# LRFDMDM32 register map
Vendor: Texas Instruments
Peripheral module from a debugger description file (folder CC27xxx15).
Registers are 32-bit, access per field, reset 0x0 unless marked. A register's access mark holds for its fields unless they carry their own. Offsets are as the file gives them; lines under a group give offsets from that group; [hi:lo] are bit positions; {n}, {i} and the like mark numbered series; 'fields as' and 'values as' point back to an identical list; <NAME> marks a mode.

## LRFDMDM32 (part 1 of 2)
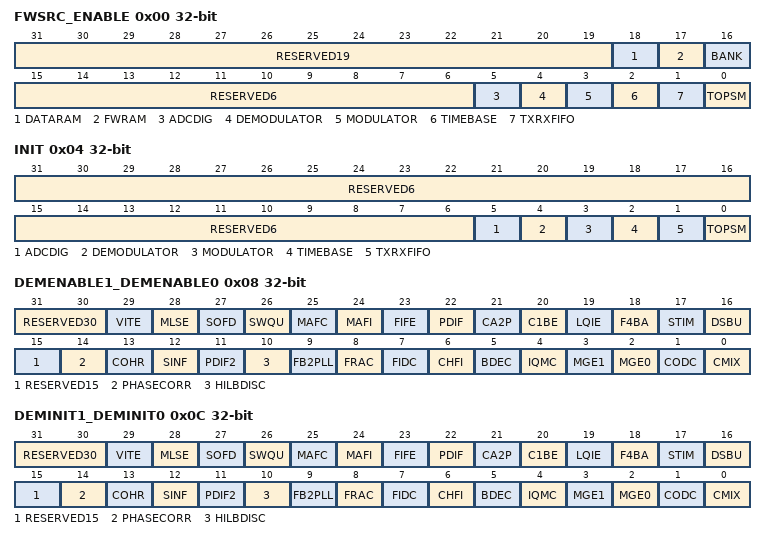
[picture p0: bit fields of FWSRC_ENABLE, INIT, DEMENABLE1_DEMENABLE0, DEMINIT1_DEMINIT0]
0x00 FWSRC_ENABLE — Internal. Only to be used through TI provided API.
  [31:19] RESERVED19 ro — Internal. Only to be used through TI provided API.
  [18] DATARAM rw — Internal. Only to be used through TI provided API.
    1=S2RRAM (Internal. Only to be used through TI provided API.); 0=MDMRAM (Internal. Only to be used through TI provided API.)
  [17] FWRAM rw — Internal. Only to be used through TI provided API.
    values as DATARAM
  [16] BANK rw — Internal. Only to be used through TI provided API.
    1=ONE (Internal. Only to be used through TI provided API.); 0=ZERO (Internal. Only to be used through TI provided API.)
  [15:6] RESERVED6 ro — Internal. Only to be used through TI provided API.
  [5] ADCDIG rw — Internal. Only to be used through TI provided API.
    1=EN (Internal. Only to be used through TI provided API.); 0=DIS (Internal. Only to be used through TI provided API.)
  [4] DEMODULATOR rw — Internal. Only to be used through TI provided API.
    values as ADCDIG
  [3] MODULATOR rw — Internal. Only to be used through TI provided API.
    values as ADCDIG
  [2] TIMEBASE rw — Internal. Only to be used through TI provided API.
    values as ADCDIG
  [1] TXRXFIFO rw — Internal. Only to be used through TI provided API.
    values as ADCDIG
  [0] TOPSM rw — Internal. Only to be used through TI provided API.
    values as ADCDIG
0x04 INIT — Internal. Only to be used through TI provided API.
  [31:6] RESERVED6 ro — Internal. Only to be used through TI provided API.
  [5] ADCDIG wo — Internal. Only to be used through TI provided API.
    1=RESET (Internal. Only to be used through TI provided API.); 0=NO_EFFECT (Internal. Only to be used through TI provided API.)
  [4] DEMODULATOR wo — Internal. Only to be used through TI provided API.
    values as ADCDIG
  [3] MODULATOR wo — Internal. Only to be used through TI provided API.
    values as ADCDIG
  [2] TIMEBASE wo — Internal. Only to be used through TI provided API.
    values as ADCDIG
  [1] TXRXFIFO wo — Internal. Only to be used through TI provided API.
    values as ADCDIG
  [0] TOPSM wo — Internal. Only to be used through TI provided API.
    values as ADCDIG
0x08 DEMENABLE1_DEMENABLE0 — Internal. Only to be used through TI provided API.
  [31:30] RESERVED30 ro — Internal. Only to be used through TI provided API.
  [29] VITE rw — Internal. Only to be used through TI provided API.
    values as FWSRC_ENABLE.ADCDIG
  [28] MLSE rw — Internal. Only to be used through TI provided API.
    values as FWSRC_ENABLE.ADCDIG
  [27] SOFD rw — Internal. Only to be used through TI provided API.
    values as FWSRC_ENABLE.ADCDIG
  [26] SWQU rw — Internal. Only to be used through TI provided API.
    values as FWSRC_ENABLE.ADCDIG
  [25] MAFC rw — Internal. Only to be used through TI provided API.
    values as FWSRC_ENABLE.ADCDIG
  [24] MAFI rw — Internal. Only to be used through TI provided API.
    values as FWSRC_ENABLE.ADCDIG
  [23] FIFE rw — Internal. Only to be used through TI provided API.
    values as FWSRC_ENABLE.ADCDIG
  [22] PDIF rw — Internal. Only to be used through TI provided API.
    values as FWSRC_ENABLE.ADCDIG
  [21] CA2P rw — Internal. Only to be used through TI provided API.
    values as FWSRC_ENABLE.ADCDIG
  [20] C1BE rw — Internal. Only to be used through TI provided API.
    values as FWSRC_ENABLE.ADCDIG
  [19] LQIE rw — Internal. Only to be used through TI provided API.
    values as FWSRC_ENABLE.ADCDIG
  [18] F4BA rw — Internal. Only to be used through TI provided API.
    values as FWSRC_ENABLE.ADCDIG
  [17] STIM rw — Internal. Only to be used through TI provided API.
    values as FWSRC_ENABLE.ADCDIG
  [16] DSBU rw — Internal. Only to be used through TI provided API.
    values as FWSRC_ENABLE.ADCDIG
  [15] RESERVED15 ro — Internal. Only to be used through TI provided API.
  [14] PHASECORR rw — Internal. Only to be used through TI provided API.
  [13] COHR rw — Internal. Only to be used through TI provided API.
  [12] SINF rw — Internal. Only to be used through TI provided API.
  [11] PDIF2 rw — Internal. Only to be used through TI provided API.
  [10] HILBDISC rw — Internal. Only to be used through TI provided API.
  [9] FB2PLL rw — Internal. Only to be used through TI provided API.
  [8] FRAC rw — Internal. Only to be used through TI provided API.
    values as FWSRC_ENABLE.ADCDIG
  [7] FIDC rw — Internal. Only to be used through TI provided API.
    values as FWSRC_ENABLE.ADCDIG
  [6] CHFI rw — Internal. Only to be used through TI provided API.
    values as FWSRC_ENABLE.ADCDIG
  [5] BDEC rw — Internal. Only to be used through TI provided API.
    values as FWSRC_ENABLE.ADCDIG
  [4] IQMC rw — Internal. Only to be used through TI provided API.
    values as FWSRC_ENABLE.ADCDIG
  [3] MGE1 rw — Internal. Only to be used through TI provided API.
    values as FWSRC_ENABLE.ADCDIG
  [2] MGE0 rw — Internal. Only to be used through TI provided API.
    values as FWSRC_ENABLE.ADCDIG
  [1] CODC rw — Internal. Only to be used through TI provided API.
    values as FWSRC_ENABLE.ADCDIG
  [0] CMIX rw — Internal. Only to be used through TI provided API.
    values as FWSRC_ENABLE.ADCDIG
0x0C DEMINIT1_DEMINIT0 — Internal. Only to be used through TI provided API.
  [31:30] RESERVED30 ro — Internal. Only to be used through TI provided API.
  [29] VITE wo — Internal. Only to be used through TI provided API.
    values as INIT.ADCDIG
  [28] MLSE wo — Internal. Only to be used through TI provided API.
    values as INIT.ADCDIG
  [27] SOFD wo — Internal. Only to be used through TI provided API.
    values as INIT.ADCDIG
  [26] SWQU wo — Internal. Only to be used through TI provided API.
    values as INIT.ADCDIG
  [25] MAFC wo — Internal. Only to be used through TI provided API.
    values as INIT.ADCDIG
  [24] MAFI wo — Internal. Only to be used through TI provided API.
    values as INIT.ADCDIG
  [23] FIFE wo — Internal. Only to be used through TI provided API.
    values as INIT.ADCDIG
  [22] PDIF wo — Internal. Only to be used through TI provided API.
    values as INIT.ADCDIG
  [21] CA2P wo — Internal. Only to be used through TI provided API.
    values as INIT.ADCDIG
  [20] C1BE wo — Internal. Only to be used through TI provided API.
    values as INIT.ADCDIG
  [19] LQIE wo — Internal. Only to be used through TI provided API.
    values as INIT.ADCDIG
  [18] F4BA wo — Internal. Only to be used through TI provided API.
    values as INIT.ADCDIG
  [17] STIM wo — Internal. Only to be used through TI provided API.
    values as INIT.ADCDIG
  [16] DSBU wo — Internal. Only to be used through TI provided API.
    values as INIT.ADCDIG
  [15] RESERVED15 ro — Internal. Only to be used through TI provided API.
  [14] PHASECORR wo — Internal. Only to be used through TI provided API.
  [13] COHR wo — Internal. Only to be used through TI provided API.
  [12] SINF wo — Internal. Only to be used through TI provided API.
  [11] PDIF2 wo — Internal. Only to be used through TI provided API.
  [10] HILBDISC wo — Internal. Only to be used through TI provided API.
  [9] FB2PLL wo — Internal. Only to be used through TI provided API.
  [8] FRAC wo — Internal. Only to be used through TI provided API.
    values as INIT.ADCDIG
  [7] FIDC wo — Internal. Only to be used through TI provided API.
    values as INIT.ADCDIG
  [6] CHFI wo — Internal. Only to be used through TI provided API.
    values as INIT.ADCDIG
  [5] BDEC wo — Internal. Only to be used through TI provided API.
    values as INIT.ADCDIG
  [4] IQMC wo — Internal. Only to be used through TI provided API.
    values as INIT.ADCDIG
  [3] MGE1 wo — Internal. Only to be used through TI provided API.
    values as INIT.ADCDIG
  [2] MGE0 wo — Internal. Only to be used through TI provided API.
    values as INIT.ADCDIG
  [1] CODC wo — Internal. Only to be used through TI provided API.
    values as INIT.ADCDIG
  [0] CMIX wo — Internal. Only to be used through TI provided API.
    values as INIT.ADCDIG
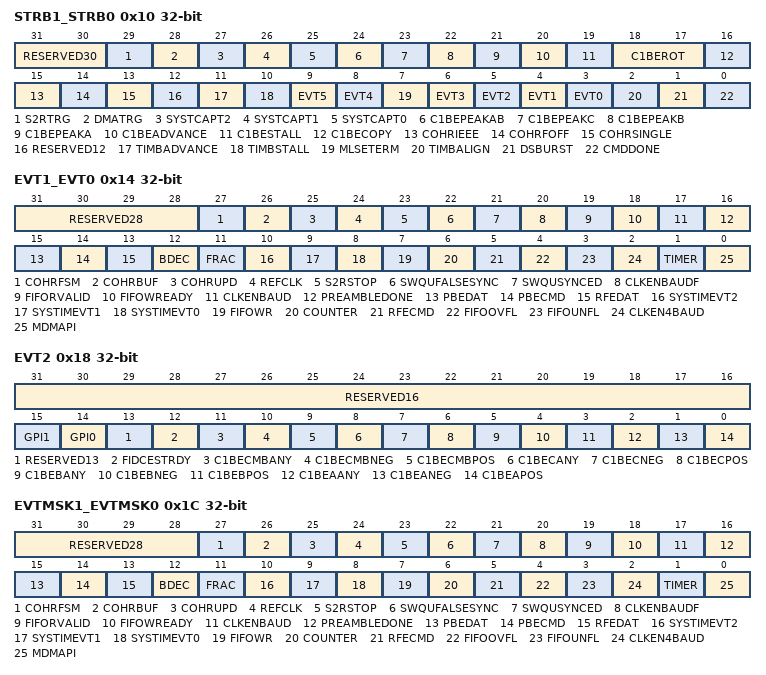
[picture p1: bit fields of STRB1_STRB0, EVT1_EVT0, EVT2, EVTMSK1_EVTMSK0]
0x10 STRB1_STRB0 — Internal. Only to be used through TI provided API.
  [31:30] RESERVED30 ro — Internal. Only to be used through TI provided API.
  [29] S2RTRG wo — Internal. Only to be used through TI provided API.
    values as FWSRC_ENABLE.BANK
  [28] DMATRG wo — Internal. Only to be used through TI provided API.
    values as FWSRC_ENABLE.BANK
  [27] SYSTCAPT2 wo — Internal. Only to be used through TI provided API.
    values as FWSRC_ENABLE.BANK
  [26] SYSTCAPT1 wo — Internal. Only to be used through TI provided API.
    values as FWSRC_ENABLE.BANK
  [25] SYSTCAPT0 wo — Internal. Only to be used through TI provided API.
    values as FWSRC_ENABLE.BANK
  [24] C1BEPEAKAB wo — Internal. Only to be used through TI provided API.
    values as FWSRC_ENABLE.BANK
  [23] C1BEPEAKC wo — Internal. Only to be used through TI provided API.
    values as FWSRC_ENABLE.BANK
  [22] C1BEPEAKB wo — Internal. Only to be used through TI provided API.
    values as FWSRC_ENABLE.BANK
  [21] C1BEPEAKA wo — Internal. Only to be used through TI provided API.
    values as FWSRC_ENABLE.BANK
  [20] C1BEADVANCE wo — Internal. Only to be used through TI provided API.
    values as FWSRC_ENABLE.BANK
  [19] C1BESTALL wo — Internal. Only to be used through TI provided API.
    values as FWSRC_ENABLE.BANK
  [18:17] C1BEROT wo — Internal. Only to be used through TI provided API.
    3=ROT16R (Internal. Only to be used through TI provided API.); 2=ROT1L (Internal. Only to be used through TI provided API.); 1=ROT1R (Internal. Only to be used through TI provided API.); 0=ROT0 (Internal. Only to be used through TI provided API.)
  [16] C1BECOPY wo — Internal. Only to be used through TI provided API.
    values as FWSRC_ENABLE.BANK
  [15] COHRIEEE wo — Internal. Only to be used through TI provided API.
  [14] COHRFOFF wo — Internal. Only to be used through TI provided API.
  [13] COHRSINGLE wo — Internal. Only to be used through TI provided API.
  [12] RESERVED12 ro — Internal. Only to be used through TI provided API.
  [11] TIMBADVANCE wo — Internal. Only to be used through TI provided API.
    1=ON (Internal. Only to be used through TI provided API.); 0=NO_EFFECT (Internal. Only to be used through TI provided API.)
  [10] TIMBSTALL wo — Internal. Only to be used through TI provided API.
    values as TIMBADVANCE
  [9] EVT5 wo — Internal. Only to be used through TI provided API.
    values as FWSRC_ENABLE.BANK
  [8] EVT4 wo — Internal. Only to be used through TI provided API.
    values as FWSRC_ENABLE.BANK
  [7] MLSETERM wo — Internal. Only to be used through TI provided API.
    1=ON (Internal. Only to be used through TI provided API.); 0=OFF (Internal. Only to be used through TI provided API.)
  [n+3] EVT{n} wo (n=0..3) — Internal. Only to be used through TI provided API.
    values as FWSRC_ENABLE.BANK
  [2] TIMBALIGN wo — Internal. Only to be used through TI provided API.
    values as TIMBADVANCE
  [1] DSBURST wo — Internal. Only to be used through TI provided API.
    1=RESTART (Internal. Only to be used through TI provided API.); 0=NO_EFFECT (Internal. Only to be used through TI provided API.)
  [0] CMDDONE wo — Internal. Only to be used through TI provided API.
    1=YES (Internal. Only to be used through TI provided API.); 0=NO (Internal. Only to be used through TI provided API.)
0x14 EVT1_EVT0 ro — Internal. Only to be used through TI provided API.
  [31:28] RESERVED28 — Internal. Only to be used through TI provided API.
  [27] COHRFSM — Internal. Only to be used through TI provided API.
  [26] COHRBUF — Internal. Only to be used through TI provided API.
  [25] COHRUPD — Internal. Only to be used through TI provided API.
  [24] REFCLK — Internal. Only to be used through TI provided API.
    values as FWSRC_ENABLE.BANK
  [23] S2RSTOP — Internal. Only to be used through TI provided API.
    values as FWSRC_ENABLE.BANK
  [22] SWQUFALSESYNC — Internal. Only to be used through TI provided API.
    values as FWSRC_ENABLE.BANK
  [21] SWQUSYNCED — Internal. Only to be used through TI provided API.
    values as FWSRC_ENABLE.BANK
  [20] CLKENBAUDF — Internal. Only to be used through TI provided API.
    values as FWSRC_ENABLE.BANK
  [19] FIFORVALID — Internal. Only to be used through TI provided API.
    values as FWSRC_ENABLE.BANK
  [18] FIFOWREADY — Internal. Only to be used through TI provided API.
    values as FWSRC_ENABLE.BANK
  [17] CLKENBAUD — Internal. Only to be used through TI provided API.
    values as FWSRC_ENABLE.BANK
  [16] PREAMBLEDONE — Internal. Only to be used through TI provided API.
    values as FWSRC_ENABLE.BANK
  [15] PBEDAT — Internal. Only to be used through TI provided API.
    values as FWSRC_ENABLE.BANK
  [14] PBECMD — Internal. Only to be used through TI provided API.
    values as FWSRC_ENABLE.BANK
  [13] RFEDAT — Internal. Only to be used through TI provided API.
    values as FWSRC_ENABLE.BANK
  [12] BDEC — Internal. Only to be used through TI provided API.
    values as FWSRC_ENABLE.BANK
  [11] FRAC — Internal. Only to be used through TI provided API.
    values as FWSRC_ENABLE.BANK
  [10] SYSTIMEVT2 — Internal. Only to be used through TI provided API.
    values as FWSRC_ENABLE.BANK
  [9] SYSTIMEVT1 — Internal. Only to be used through TI provided API.
    values as FWSRC_ENABLE.BANK
  [8] SYSTIMEVT0 — Internal. Only to be used through TI provided API.
    values as FWSRC_ENABLE.BANK
  [7] FIFOWR — Internal. Only to be used through TI provided API.
    values as FWSRC_ENABLE.BANK
  [6] COUNTER — Internal. Only to be used through TI provided API.
    values as FWSRC_ENABLE.BANK
  [5] RFECMD — Internal. Only to be used through TI provided API.
    values as FWSRC_ENABLE.BANK
  [4] FIFOOVFL — Internal. Only to be used through TI provided API.
    values as FWSRC_ENABLE.BANK
  [3] FIFOUNFL — Internal. Only to be used through TI provided API.
    values as FWSRC_ENABLE.BANK
  [2] CLKEN4BAUD — Internal. Only to be used through TI provided API.
    values as FWSRC_ENABLE.BANK
  [1] TIMER — Internal. Only to be used through TI provided API.
    values as FWSRC_ENABLE.BANK
  [0] MDMAPI — Internal. Only to be used through TI provided API.
    values as FWSRC_ENABLE.BANK
0x18 EVT2 ro — Internal. Only to be used through TI provided API.
  [31:16] RESERVED16 — Internal. Only to be used through TI provided API.
  [15] GPI1 — Internal. Only to be used through TI provided API.
    values as FWSRC_ENABLE.BANK
  [14] GPI0 — Internal. Only to be used through TI provided API.
    values as FWSRC_ENABLE.BANK
  [13] RESERVED13 — Internal. Only to be used through TI provided API.
  [12] FIDCESTRDY — Internal. Only to be used through TI provided API.
    values as FWSRC_ENABLE.BANK
  [11] C1BECMBANY — Internal. Only to be used through TI provided API.
    values as FWSRC_ENABLE.BANK
  [10] C1BECMBNEG — Internal. Only to be used through TI provided API.
    values as FWSRC_ENABLE.BANK
  [9] C1BECMBPOS — Internal. Only to be used through TI provided API.
    values as FWSRC_ENABLE.BANK
  [8] C1BECANY — Internal. Only to be used through TI provided API.
    values as FWSRC_ENABLE.BANK
  [7] C1BECNEG — Internal. Only to be used through TI provided API.
    values as FWSRC_ENABLE.BANK
  [6] C1BECPOS — Internal. Only to be used through TI provided API.
    values as FWSRC_ENABLE.BANK
  [5] C1BEBANY — Internal. Only to be used through TI provided API.
    values as FWSRC_ENABLE.BANK
  [4] C1BEBNEG — Internal. Only to be used through TI provided API.
    values as FWSRC_ENABLE.BANK
  [3] C1BEBPOS — Internal. Only to be used through TI provided API.
    values as FWSRC_ENABLE.BANK
  [2] C1BEAANY — Internal. Only to be used through TI provided API.
    values as FWSRC_ENABLE.BANK
  [1] C1BEANEG — Internal. Only to be used through TI provided API.
    values as FWSRC_ENABLE.BANK
  [0] C1BEAPOS — Internal. Only to be used through TI provided API.
    values as FWSRC_ENABLE.BANK
0x1C EVTMSK1_EVTMSK0 — Internal. Only to be used through TI provided API.
  [31:28] RESERVED28 ro — Internal. Only to be used through TI provided API.
  [27] COHRFSM rw — Internal. Only to be used through TI provided API.
  [26] COHRBUF rw — Internal. Only to be used through TI provided API.
  [25] COHRUPD rw — Internal. Only to be used through TI provided API.
  [24] REFCLK rw — Internal. Only to be used through TI provided API.
    values as FWSRC_ENABLE.ADCDIG
  [23] S2RSTOP rw — Internal. Only to be used through TI provided API.
    values as FWSRC_ENABLE.ADCDIG
  [22] SWQUFALSESYNC rw — Internal. Only to be used through TI provided API.
    values as FWSRC_ENABLE.ADCDIG
  [21] SWQUSYNCED rw — Internal. Only to be used through TI provided API.
    values as FWSRC_ENABLE.ADCDIG
  [20] CLKENBAUDF rw — Internal. Only to be used through TI provided API.
    values as FWSRC_ENABLE.ADCDIG
  [19] FIFORVALID rw — Internal. Only to be used through TI provided API.
    values as FWSRC_ENABLE.ADCDIG
  [18] FIFOWREADY rw — Internal. Only to be used through TI provided API.
    values as FWSRC_ENABLE.ADCDIG
  [17] CLKENBAUD rw — Internal. Only to be used through TI provided API.
    values as FWSRC_ENABLE.ADCDIG
  [16] PREAMBLEDONE rw — Internal. Only to be used through TI provided API.
    values as FWSRC_ENABLE.ADCDIG
  [15] PBEDAT rw — Internal. Only to be used through TI provided API.
    values as FWSRC_ENABLE.ADCDIG
  [14] PBECMD rw — Internal. Only to be used through TI provided API.
    values as FWSRC_ENABLE.ADCDIG
  [13] RFEDAT rw — Internal. Only to be used through TI provided API.
    values as FWSRC_ENABLE.ADCDIG
  [12] BDEC rw — Internal. Only to be used through TI provided API.
    values as FWSRC_ENABLE.ADCDIG
  [11] FRAC rw — Internal. Only to be used through TI provided API.
    values as FWSRC_ENABLE.ADCDIG
  [10] SYSTIMEVT2 rw — Internal. Only to be used through TI provided API.
    values as FWSRC_ENABLE.ADCDIG
  [9] SYSTIMEVT1 rw — Internal. Only to be used through TI provided API.
    values as FWSRC_ENABLE.ADCDIG
  [8] SYSTIMEVT0 rw — Internal. Only to be used through TI provided API.
    values as FWSRC_ENABLE.ADCDIG
  [7] FIFOWR rw — Internal. Only to be used through TI provided API.
    values as FWSRC_ENABLE.ADCDIG
  [6] COUNTER rw — Internal. Only to be used through TI provided API.
    values as FWSRC_ENABLE.ADCDIG
  [5] RFECMD rw — Internal. Only to be used through TI provided API.
    values as FWSRC_ENABLE.ADCDIG
  [4] FIFOOVFL rw — Internal. Only to be used through TI provided API.
    values as FWSRC_ENABLE.ADCDIG
  [3] FIFOUNFL rw — Internal. Only to be used through TI provided API.
    values as FWSRC_ENABLE.ADCDIG
  [2] CLKEN4BAUD rw — Internal. Only to be used through TI provided API.
    values as FWSRC_ENABLE.ADCDIG
  [1] TIMER rw — Internal. Only to be used through TI provided API.
    values as FWSRC_ENABLE.ADCDIG
  [0] MDMAPI rw — Internal. Only to be used through TI provided API.
    values as FWSRC_ENABLE.ADCDIG
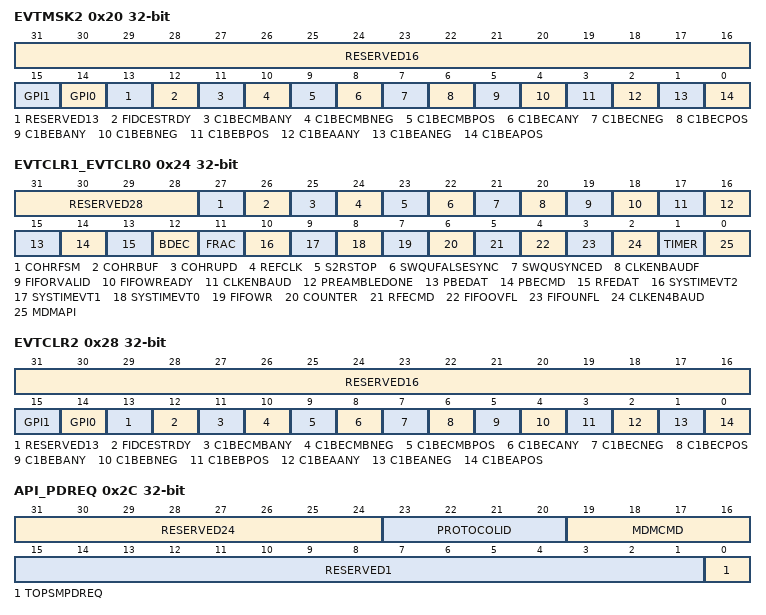
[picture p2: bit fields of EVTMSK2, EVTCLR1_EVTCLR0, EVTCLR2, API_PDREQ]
0x20 EVTMSK2 — Internal. Only to be used through TI provided API.
  [31:16] RESERVED16 ro — Internal. Only to be used through TI provided API.
  [15] GPI1 rw — Internal. Only to be used through TI provided API.
    values as FWSRC_ENABLE.ADCDIG
  [14] GPI0 rw — Internal. Only to be used through TI provided API.
    values as FWSRC_ENABLE.ADCDIG
  [13] RESERVED13 ro — Internal. Only to be used through TI provided API.
  [12] FIDCESTRDY rw — Internal. Only to be used through TI provided API.
    values as FWSRC_ENABLE.ADCDIG
  [11] C1BECMBANY rw — Internal. Only to be used through TI provided API.
    values as FWSRC_ENABLE.ADCDIG
  [10] C1BECMBNEG rw — Internal. Only to be used through TI provided API.
    values as FWSRC_ENABLE.ADCDIG
  [9] C1BECMBPOS rw — Internal. Only to be used through TI provided API.
    values as FWSRC_ENABLE.ADCDIG
  [8] C1BECANY rw — Internal. Only to be used through TI provided API.
    values as FWSRC_ENABLE.ADCDIG
  [7] C1BECNEG rw — Internal. Only to be used through TI provided API.
    values as FWSRC_ENABLE.ADCDIG
  [6] C1BECPOS rw — Internal. Only to be used through TI provided API.
    values as FWSRC_ENABLE.ADCDIG
  [5] C1BEBANY rw — Internal. Only to be used through TI provided API.
    values as FWSRC_ENABLE.ADCDIG
  [4] C1BEBNEG rw — Internal. Only to be used through TI provided API.
    values as FWSRC_ENABLE.ADCDIG
  [3] C1BEBPOS rw — Internal. Only to be used through TI provided API.
    values as FWSRC_ENABLE.ADCDIG
  [2] C1BEAANY rw — Internal. Only to be used through TI provided API.
    values as FWSRC_ENABLE.ADCDIG
  [1] C1BEANEG rw — Internal. Only to be used through TI provided API.
    values as FWSRC_ENABLE.ADCDIG
  [0] C1BEAPOS rw — Internal. Only to be used through TI provided API.
    values as FWSRC_ENABLE.ADCDIG
0x24 EVTCLR1_EVTCLR0 — Internal. Only to be used through TI provided API.
  [31:28] RESERVED28 ro — Internal. Only to be used through TI provided API.
  [27] COHRFSM wo — Internal. Only to be used through TI provided API.
  [26] COHRBUF wo — Internal. Only to be used through TI provided API.
  [25] COHRUPD wo — Internal. Only to be used through TI provided API.
  [24] REFCLK wo — Internal. Only to be used through TI provided API.
    1=CLEAR (Internal. Only to be used through TI provided API.); 0=RETAIN (Internal. Only to be used through TI provided API.)
  [23] S2RSTOP wo — Internal. Only to be used through TI provided API.
    values as REFCLK
  [22] SWQUFALSESYNC wo — Internal. Only to be used through TI provided API.
    values as REFCLK
  [21] SWQUSYNCED wo — Internal. Only to be used through TI provided API.
    values as REFCLK
  [20] CLKENBAUDF wo — Internal. Only to be used through TI provided API.
    values as REFCLK
  [19] FIFORVALID wo — Internal. Only to be used through TI provided API.
    values as REFCLK
  [18] FIFOWREADY wo — Internal. Only to be used through TI provided API.
    values as REFCLK
  [17] CLKENBAUD wo — Internal. Only to be used through TI provided API.
    values as REFCLK
  [16] PREAMBLEDONE wo — Internal. Only to be used through TI provided API.
    values as REFCLK
  [15] PBEDAT wo — Internal. Only to be used through TI provided API.
    values as REFCLK
  [14] PBECMD wo — Internal. Only to be used through TI provided API.
    values as REFCLK
  [13] RFEDAT wo — Internal. Only to be used through TI provided API.
    values as REFCLK
  [12] BDEC wo — Internal. Only to be used through TI provided API.
    values as REFCLK
  [11] FRAC wo — Internal. Only to be used through TI provided API.
    values as REFCLK
  [10] SYSTIMEVT2 wo — Internal. Only to be used through TI provided API.
    values as REFCLK
  [9] SYSTIMEVT1 wo — Internal. Only to be used through TI provided API.
    values as REFCLK
  [8] SYSTIMEVT0 wo — Internal. Only to be used through TI provided API.
    values as REFCLK
  [7] FIFOWR wo — Internal. Only to be used through TI provided API.
    values as REFCLK
  [6] COUNTER wo — Internal. Only to be used through TI provided API.
    values as REFCLK
  [5] RFECMD wo — Internal. Only to be used through TI provided API.
    values as REFCLK
  [4] FIFOOVFL wo — Internal. Only to be used through TI provided API.
    values as REFCLK
  [3] FIFOUNFL wo — Internal. Only to be used through TI provided API.
    values as REFCLK
  [2] CLKEN4BAUD wo — Internal. Only to be used through TI provided API.
    values as REFCLK
  [1] TIMER wo — Internal. Only to be used through TI provided API.
    values as REFCLK
  [0] MDMAPI wo — Internal. Only to be used through TI provided API.
    values as REFCLK
0x28 EVTCLR2 — Internal. Only to be used through TI provided API.
  [31:16] RESERVED16 ro — Internal. Only to be used through TI provided API.
  [15] GPI1 wo — Internal. Only to be used through TI provided API.
    values as EVTCLR1_EVTCLR0.REFCLK
  [14] GPI0 wo — Internal. Only to be used through TI provided API.
    values as EVTCLR1_EVTCLR0.REFCLK
  [13] RESERVED13 ro — Internal. Only to be used through TI provided API.
  [12] FIDCESTRDY wo — Internal. Only to be used through TI provided API.
    values as EVTCLR1_EVTCLR0.REFCLK
  [11] C1BECMBANY wo — Internal. Only to be used through TI provided API.
    values as EVTCLR1_EVTCLR0.REFCLK
  [10] C1BECMBNEG wo — Internal. Only to be used through TI provided API.
    values as EVTCLR1_EVTCLR0.REFCLK
  [9] C1BECMBPOS wo — Internal. Only to be used through TI provided API.
    values as EVTCLR1_EVTCLR0.REFCLK
  [8] C1BECANY wo — Internal. Only to be used through TI provided API.
    values as EVTCLR1_EVTCLR0.REFCLK
  [7] C1BECNEG wo — Internal. Only to be used through TI provided API.
    values as EVTCLR1_EVTCLR0.REFCLK
  [6] C1BECPOS wo — Internal. Only to be used through TI provided API.
    values as EVTCLR1_EVTCLR0.REFCLK
  [5] C1BEBANY wo — Internal. Only to be used through TI provided API.
    values as EVTCLR1_EVTCLR0.REFCLK
  [4] C1BEBNEG wo — Internal. Only to be used through TI provided API.
    values as EVTCLR1_EVTCLR0.REFCLK
  [3] C1BEBPOS wo — Internal. Only to be used through TI provided API.
    values as EVTCLR1_EVTCLR0.REFCLK
  [2] C1BEAANY wo — Internal. Only to be used through TI provided API.
    values as EVTCLR1_EVTCLR0.REFCLK
  [1] C1BEANEG wo — Internal. Only to be used through TI provided API.
    values as EVTCLR1_EVTCLR0.REFCLK
  [0] C1BEAPOS wo — Internal. Only to be used through TI provided API.
    values as EVTCLR1_EVTCLR0.REFCLK
0x2C API_PDREQ — Internal. Only to be used through TI provided API.
  [31:24] RESERVED24 ro — Internal. Only to be used through TI provided API.
  [23:20] PROTOCOLID ro — Internal. Only to be used through TI provided API.
    15=ALLONES (Internal. Only to be used through TI provided API.); 0=ALLZEROS (Internal. Only to be used through TI provided API.)
  [19:16] MDMCMD ro — Internal. Only to be used through TI provided API.
    values as PROTOCOLID
  [15:1] RESERVED1 ro — Internal. Only to be used through TI provided API.
  [0] TOPSMPDREQ rw — Internal. Only to be used through TI provided API.
    values as STRB1_STRB0.MLSETERM
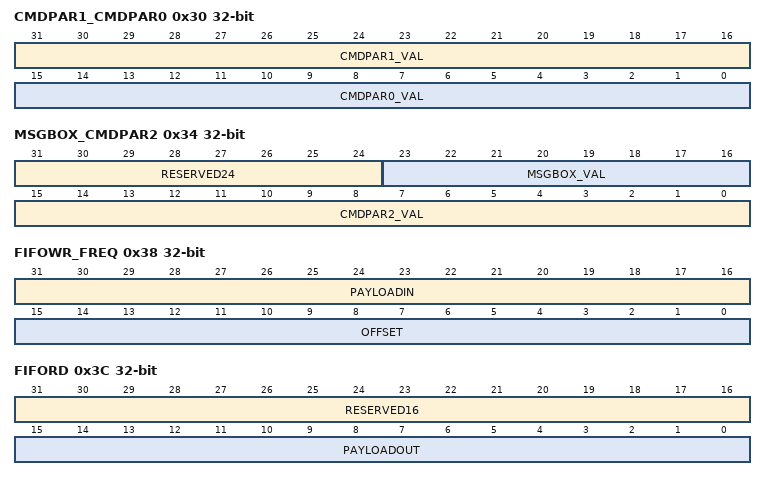
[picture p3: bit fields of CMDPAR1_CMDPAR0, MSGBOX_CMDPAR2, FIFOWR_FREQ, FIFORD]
0x30 CMDPAR1_CMDPAR0 ro — Internal. Only to be used through TI provided API.
  [31:16] CMDPAR1_VAL — Internal. Only to be used through TI provided API.
    0xFFFF=ALLONES (Internal. Only to be used through TI provided API.); 0=ALLZEROS (Internal. Only to be used through TI provided API.)
  [15:0] CMDPAR0_VAL — Internal. Only to be used through TI provided API.
    values as CMDPAR1_VAL
0x34 MSGBOX_CMDPAR2 — Internal. Only to be used through TI provided API.
  [31:24] RESERVED24 ro — Internal. Only to be used through TI provided API.
  [23:16] MSGBOX_VAL rw — Internal. Only to be used through TI provided API.
    255=ALLONES (Internal. Only to be used through TI provided API.); 0=ALLZEROS (Internal. Only to be used through TI provided API.)
  [15:0] CMDPAR2_VAL ro — Internal. Only to be used through TI provided API.
    values as CMDPAR1_CMDPAR0.CMDPAR1_VAL
0x38 FIFOWR_FREQ rw — Internal. Only to be used through TI provided API.
  [31:16] PAYLOADIN — Internal. Only to be used through TI provided API.
    values as CMDPAR1_CMDPAR0.CMDPAR1_VAL
  [15:0] OFFSET — Internal. Only to be used through TI provided API.
    values as CMDPAR1_CMDPAR0.CMDPAR1_VAL
0x3C FIFORD ro — Internal. Only to be used through TI provided API.
  [31:16] RESERVED16 — Internal. Only to be used through TI provided API.
  [15:0] PAYLOADOUT — Internal. Only to be used through TI provided API.
    values as CMDPAR1_CMDPAR0.CMDPAR1_VAL
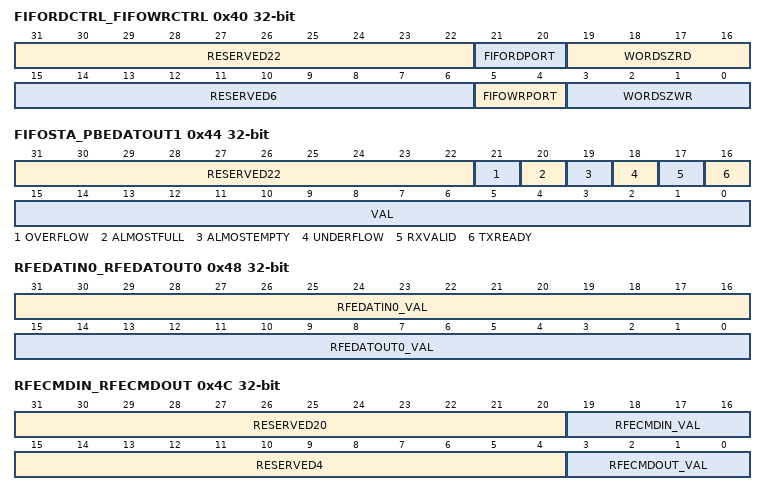
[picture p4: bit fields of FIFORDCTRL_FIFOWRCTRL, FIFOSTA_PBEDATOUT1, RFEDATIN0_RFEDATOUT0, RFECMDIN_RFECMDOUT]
0x40 FIFORDCTRL_FIFOWRCTRL — Internal. Only to be used through TI provided API.
  [31:22] RESERVED22 ro — Internal. Only to be used through TI provided API.
  [21:20] FIFORDPORT rw — Internal. Only to be used through TI provided API.
    2=PBE (Internal. Only to be used through TI provided API.); 1=MODEM (Internal. Only to be used through TI provided API.); 0=MDMFIFORD (Internal. Only to be used through TI provided API.)
  [19:16] WORDSZRD rw — Internal. Only to be used through TI provided API.
    {v}=BITS{v+1} (Internal. Only to be used through TI provided API.) (v=0..15)
  [15:6] RESERVED6 ro — Internal. Only to be used through TI provided API.
  [5:4] FIFOWRPORT rw — Internal. Only to be used through TI provided API.
    2=PBE (Internal. Only to be used through TI provided API.); 1=MODEM (Internal. Only to be used through TI provided API.); 0=MDMFIFOWR (Internal. Only to be used through TI provided API.)
  [3:0] WORDSZWR rw — Internal. Only to be used through TI provided API.
    values as WORDSZRD
0x44 FIFOSTA_PBEDATOUT1 — Internal. Only to be used through TI provided API.
  [31:22] RESERVED22 ro — Internal. Only to be used through TI provided API.
  [21] OVERFLOW ro — Internal. Only to be used through TI provided API.
    values as FWSRC_ENABLE.BANK
  [20] ALMOSTFULL ro — Internal. Only to be used through TI provided API.
    values as FWSRC_ENABLE.BANK
  [19] ALMOSTEMPTY ro — Internal. Only to be used through TI provided API.
    values as FWSRC_ENABLE.BANK
  [18] UNDERFLOW ro — Internal. Only to be used through TI provided API.
    values as FWSRC_ENABLE.BANK
  [17] RXVALID ro — Internal. Only to be used through TI provided API.
    values as FWSRC_ENABLE.BANK
  [16] TXREADY ro — Internal. Only to be used through TI provided API.
    values as FWSRC_ENABLE.BANK
  [15:0] VAL rw — Internal. Only to be used through TI provided API.
    values as CMDPAR1_CMDPAR0.CMDPAR1_VAL
0x48 RFEDATIN0_RFEDATOUT0 — Internal. Only to be used through TI provided API.
  [31:16] RFEDATIN0_VAL ro — Internal. Only to be used through TI provided API.
    values as CMDPAR1_CMDPAR0.CMDPAR1_VAL
  [15:0] RFEDATOUT0_VAL rw — Internal. Only to be used through TI provided API.
    values as CMDPAR1_CMDPAR0.CMDPAR1_VAL
0x4C RFECMDIN_RFECMDOUT — Internal. Only to be used through TI provided API.
  [31:20] RESERVED20 ro — Internal. Only to be used through TI provided API.
  [19:16] RFECMDIN_VAL ro — Internal. Only to be used through TI provided API.
    values as API_PDREQ.PROTOCOLID
  [15:4] RESERVED4 ro — Internal. Only to be used through TI provided API.
  [3:0] RFECMDOUT_VAL rw — Internal. Only to be used through TI provided API.
    values as API_PDREQ.PROTOCOLID
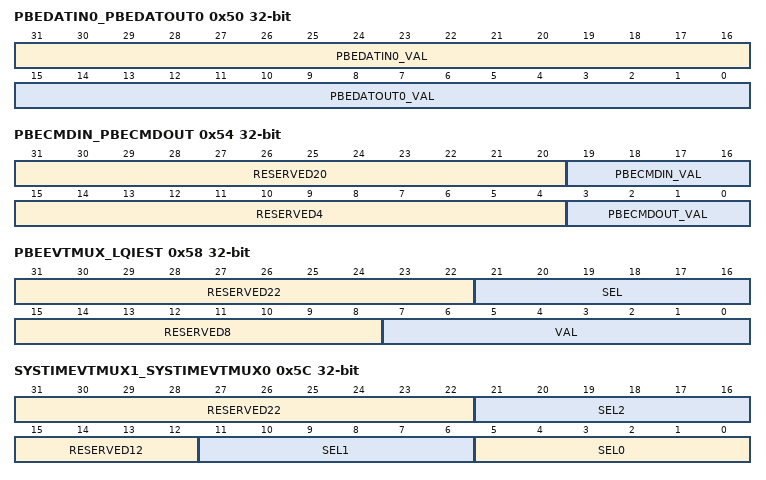
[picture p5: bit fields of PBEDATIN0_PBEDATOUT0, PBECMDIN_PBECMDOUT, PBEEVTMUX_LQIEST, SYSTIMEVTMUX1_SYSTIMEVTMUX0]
0x50 PBEDATIN0_PBEDATOUT0 — Internal. Only to be used through TI provided API.
  [31:16] PBEDATIN0_VAL ro — Internal. Only to be used through TI provided API.
    values as CMDPAR1_CMDPAR0.CMDPAR1_VAL
  [15:0] PBEDATOUT0_VAL rw — Internal. Only to be used through TI provided API.
    values as CMDPAR1_CMDPAR0.CMDPAR1_VAL
0x54 PBECMDIN_PBECMDOUT — Internal. Only to be used through TI provided API.
  [31:20] RESERVED20 ro — Internal. Only to be used through TI provided API.
  [19:16] PBECMDIN_VAL ro — Internal. Only to be used through TI provided API.
    values as API_PDREQ.PROTOCOLID
  [15:4] RESERVED4 ro — Internal. Only to be used through TI provided API.
  [3:0] PBECMDOUT_VAL rw — Internal. Only to be used through TI provided API.
    values as API_PDREQ.PROTOCOLID
0x58 PBEEVTMUX_LQIEST — Internal. Only to be used through TI provided API.
  [31:22] RESERVED22 ro — Internal. Only to be used through TI provided API.
  [21:16] SEL rw — Internal. Only to be used through TI provided API.
    63=ALLONES (Internal. Only to be used through TI provided API.); 0=ALLZEROS (Internal. Only to be used through TI provided API.)
  [15:8] RESERVED8 ro — Internal. Only to be used through TI provided API.
  [7:0] VAL rw — Internal. Only to be used through TI provided API.
    values as MSGBOX_CMDPAR2.MSGBOX_VAL
0x5C SYSTIMEVTMUX1_SYSTIMEVTMUX0 — Internal. Only to be used through TI provided API.
  [31:22] RESERVED22 ro — Internal. Only to be used through TI provided API.
  [21:16] SEL2 rw — Internal. Only to be used through TI provided API.
    values as PBEEVTMUX_LQIEST.SEL
  [15:12] RESERVED12 ro — Internal. Only to be used through TI provided API.
  [11:6] SEL1 rw — Internal. Only to be used through TI provided API.
    values as PBEEVTMUX_LQIEST.SEL
  [5:0] SEL0 rw — Internal. Only to be used through TI provided API.
    values as PBEEVTMUX_LQIEST.SEL
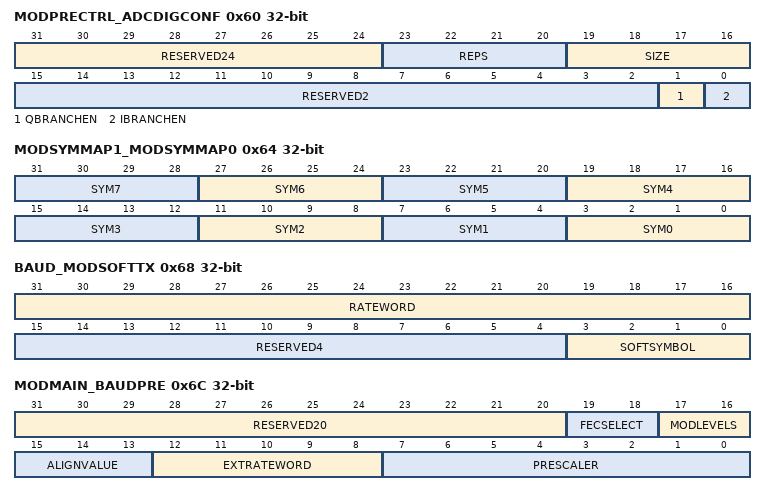
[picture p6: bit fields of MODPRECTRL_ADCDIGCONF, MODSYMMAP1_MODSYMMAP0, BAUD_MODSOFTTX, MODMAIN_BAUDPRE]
0x60 MODPRECTRL_ADCDIGCONF — Internal. Only to be used through TI provided API.
  [31:24] RESERVED24 ro — Internal. Only to be used through TI provided API.
  [23:20] REPS rw — Internal. Only to be used through TI provided API.
    {v}=Internal. Only to be used through TI provided API. (v=0..15)
  [19:16] SIZE rw — Internal. Only to be used through TI provided API.
    15=BITS16 (Internal. Only to be used through TI provided API.); 7=BITS8 (Internal. Only to be used through TI provided API.); 3=BITS4 (Internal. Only to be used through TI provided API.)
  [15:2] RESERVED2 ro — Internal. Only to be used through TI provided API.
  [1] QBRANCHEN rw — Internal. Only to be used through TI provided API.
    values as STRB1_STRB0.MLSETERM
  [0] IBRANCHEN rw — Internal. Only to be used through TI provided API.
    values as STRB1_STRB0.MLSETERM
0x64 MODSYMMAP1_MODSYMMAP0 rw — Internal. Only to be used through TI provided API.
  [all] fields
    values as API_PDREQ.PROTOCOLID
  [4n+3:4n] SYM{n} (n=0..7) — Internal. Only to be used through TI provided API.
0x68 BAUD_MODSOFTTX — Internal. Only to be used through TI provided API.
  [31:16] RATEWORD rw — Internal. Only to be used through TI provided API.
    values as CMDPAR1_CMDPAR0.CMDPAR1_VAL
  [15:4] RESERVED4 ro — Internal. Only to be used through TI provided API.
  [3:0] SOFTSYMBOL rw — Internal. Only to be used through TI provided API.
    values as API_PDREQ.PROTOCOLID
0x6C MODMAIN_BAUDPRE — Internal. Only to be used through TI provided API.
  [31:20] RESERVED20 ro — Internal. Only to be used through TI provided API.
  [19:18] FECSELECT rw — Internal. Only to be used through TI provided API.
    3=BLR (Internal. Only to be used through TI provided API.); 2=RESERVED (Internal. Only to be used through TI provided API.); 1=IEEE15_4 (Internal. Only to be used through TI provided API.); 0=NOSEL (Internal. Only to be used through TI provided API.)
  [17:16] MODLEVELS rw — Internal. Only to be used through TI provided API.
    2=LVL8 (Internal. Only to be used through TI provided API.); 1=LVL4 (Internal. Only to be used through TI provided API.); 0=LVL2 (Internal. Only to be used through TI provided API.)
  [15:13] ALIGNVALUE rw — Internal. Only to be used through TI provided API.
    7=ALLONES (Internal. Only to be used through TI provided API.); 0=ALLZEROS (Internal. Only to be used through TI provided API.)
  [12:8] EXTRATEWORD rw — Internal. Only to be used through TI provided API.
    31=ALLONES (Internal. Only to be used through TI provided API.); 0=ALLZEROS (Internal. Only to be used through TI provided API.)
  [7:0] PRESCALER rw — Internal. Only to be used through TI provided API.
    values as MSGBOX_CMDPAR2.MSGBOX_VAL
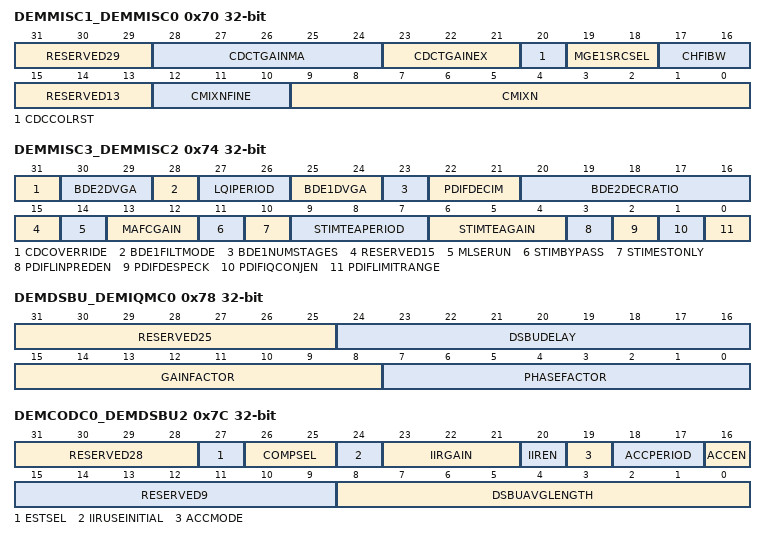
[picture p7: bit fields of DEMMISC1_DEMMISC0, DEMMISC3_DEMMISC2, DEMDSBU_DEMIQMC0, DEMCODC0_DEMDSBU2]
0x70 DEMMISC1_DEMMISC0 — Internal. Only to be used through TI provided API.
  [31:29] RESERVED29 ro — Internal. Only to be used through TI provided API.
  [28:24] CDCTGAINMA rw — Internal. Only to be used through TI provided API.
    values as MODMAIN_BAUDPRE.EXTRATEWORD
  [23:21] CDCTGAINEX rw — Internal. Only to be used through TI provided API.
    values as MODMAIN_BAUDPRE.ALIGNVALUE
  [20] CDCCOLRST rw — Internal. Only to be used through TI provided API.
    values as FWSRC_ENABLE.ADCDIG
  [19:18] MGE1SRCSEL rw — Internal. Only to be used through TI provided API.
    2=CHFI (Internal. Only to be used through TI provided API.); 1=FEXB1 (Internal. Only to be used through TI provided API.); 0=FIDC (Internal. Only to be used through TI provided API.)
  [17:16] CHFIBW rw — Internal. Only to be used through TI provided API.
    3=BW0_29 (Internal. Only to be used through TI provided API.); 2=BW0_41667 (Internal. Only to be used through TI provided API.); 1=BW0_3333 (Internal. Only to be used through TI provided API.); 0=BW0_5 (Internal. Only to be used through TI provided API.)
  [15:13] RESERVED13 ro — Internal. Only to be used through TI provided API.
  [12:10] CMIXNFINE rw — Internal. Only to be used through TI provided API.
  [9:0] CMIXN rw — Internal. Only to be used through TI provided API.
    0x3FF=ALLONES (Internal. Only to be used through TI provided API.); 0=ALLZEROS (Internal. Only to be used through TI provided API.)
0x74 DEMMISC3_DEMMISC2 — Internal. Only to be used through TI provided API.
  [31] CDCOVERRIDE rw — Internal. Only to be used through TI provided API.
  [30:29] BDE2DVGA rw — Internal. Only to be used through TI provided API.
    3=GAIN8 (Internal. Only to be used through TI provided API.); 2=GAIN4 (Internal. Only to be used through TI provided API.); 1=GAIN2 (Internal. Only to be used through TI provided API.); 0=GAIN1 (Internal. Only to be used through TI provided API.)
  [28] BDE1FILTMODE rw — Internal. Only to be used through TI provided API.
    1=DIV2 (Internal. Only to be used through TI provided API.); 0=DIV1 (Internal. Only to be used through TI provided API.)
  [27:26] LQIPERIOD rw — Internal. Only to be used through TI provided API.
    3=SYM1024 (Internal. Only to be used through TI provided API.); 2=SYM256 (Internal. Only to be used through TI provided API.); 1=SYM64 (Internal. Only to be used through TI provided API.); 0=SYM16 (Internal. Only to be used through TI provided API.)
  [25:24] BDE1DVGA rw — Internal. Only to be used through TI provided API.
    values as BDE2DVGA
  [23] BDE1NUMSTAGES rw — Internal. Only to be used through TI provided API.
    values as BDE1FILTMODE
  [22:21] PDIFDECIM rw — Internal. Only to be used through TI provided API.
    2=DIV4 (Internal. Only to be used through TI provided API.); 1=DIV2 (Internal. Only to be used through TI provided API.); 0=DIV1 (Internal. Only to be used through TI provided API.)
  [20:16] BDE2DECRATIO rw — Internal. Only to be used through TI provided API.
    3=DIV8 (Internal. Only to be used through TI provided API.); 2=DIV4 (Internal. Only to be used through TI provided API.); 1=DIV2 (Internal. Only to be used through TI provided API.); 0=DIV1 (Internal. Only to be used through TI provided API.)
  [15] RESERVED15 ro — Internal. Only to be used through TI provided API.
  [14] MLSERUN rw — Internal. Only to be used through TI provided API.
    values as FWSRC_ENABLE.ADCDIG
  [13:12] MAFCGAIN rw — Internal. Only to be used through TI provided API.
    3=ALLONES (Internal. Only to be used through TI provided API.); 0=ALLZEROS (Internal. Only to be used through TI provided API.)
  [11] STIMBYPASS rw — Internal. Only to be used through TI provided API.
    values as FWSRC_ENABLE.ADCDIG
  [10] STIMESTONLY rw — Internal. Only to be used through TI provided API.
    values as FWSRC_ENABLE.ADCDIG
  [9:7] STIMTEAPERIOD rw — Internal. Only to be used through TI provided API.
    5=SYM128 (Internal. Only to be used through TI provided API.); 4=SYM64 (Internal. Only to be used through TI provided API.); 3=SYM32 (Internal. Only to be used through TI provided API.); 2=SYM16 (Internal. Only to be used through TI provided API.); 1=SYM8 (Internal. Only to be used through TI provided API.); 0=SYM4 (Internal. Only to be used through TI provided API.)
  [6:4] STIMTEAGAIN rw — Internal. Only to be used through TI provided API.
    7=DIV4 (Internal. Only to be used through TI provided API.); 6=DIV8 (Internal. Only to be used through TI provided API.); 5=DIV16 (Internal. Only to be used through TI provided API.); 4=DIV32 (Internal. Only to be used through TI provided API.); 3=DIV64 (Internal. Only to be used through TI provided API.); 2=DIV128 (Internal. Only to be used through TI provided API.); 1=DIV256 (Internal. Only to be used through TI provided API.); 0=DIV512 (Internal. Only to be used through TI provided API.)
  [3] PDIFLINPREDEN rw — Internal. Only to be used through TI provided API.
    values as STRB1_STRB0.MLSETERM
  [2] PDIFDESPECK rw — Internal. Only to be used through TI provided API.
    values as FWSRC_ENABLE.ADCDIG
  [1] PDIFIQCONJEN rw — Internal. Only to be used through TI provided API.
    values as STRB1_STRB0.MLSETERM
  [0] PDIFLIMITRANGE rw — Internal. Only to be used through TI provided API.
    values as FWSRC_ENABLE.ADCDIG
0x78 DEMDSBU_DEMIQMC0 — Internal. Only to be used through TI provided API.
  [31:25] RESERVED25 ro — Internal. Only to be used through TI provided API.
  [24:16] DSBUDELAY rw — Internal. Only to be used through TI provided API.
    values as MSGBOX_CMDPAR2.MSGBOX_VAL
  [15:8] GAINFACTOR rw — Internal. Only to be used through TI provided API.
    values as MSGBOX_CMDPAR2.MSGBOX_VAL
  [7:0] PHASEFACTOR rw — Internal. Only to be used through TI provided API.
    values as MSGBOX_CMDPAR2.MSGBOX_VAL
0x7C DEMCODC0_DEMDSBU2 — Internal. Only to be used through TI provided API.
  [31:28] RESERVED28 ro — Internal. Only to be used through TI provided API.
  [27] ESTSEL rw — Internal. Only to be used through TI provided API.
    1=IIR (Internal. Only to be used through TI provided API.); 0=ACC (Internal. Only to be used through TI provided API.)
  [26:25] COMPSEL rw — Internal. Only to be used through TI provided API.
    3=IIR (Internal. Only to be used through TI provided API.); 2=ACC (Internal. Only to be used through TI provided API.); 0=MANUAL (Internal. Only to be used through TI provided API.)
  [24] IIRUSEINITIAL rw — Internal. Only to be used through TI provided API.
    values as FWSRC_ENABLE.ADCDIG
  [23:21] IIRGAIN rw — Internal. Only to be used through TI provided API.
    7=DIV1024 (Internal. Only to be used through TI provided API.); 6=DIV512 (Internal. Only to be used through TI provided API.); 5=DIV256 (Internal. Only to be used through TI provided API.); 4=DIV128 (Internal. Only to be used through TI provided API.); 3=DIV64 (Internal. Only to be used through TI provided API.); 2=DIV32 (Internal. Only to be used through TI provided API.); 1=DIV16 (Internal. Only to be used through TI provided API.); 0=OFF (Internal. Only to be used through TI provided API.)
  [20] IIREN rw — Internal. Only to be used through TI provided API.
    values as STRB1_STRB0.MLSETERM
  [19] ACCMODE rw — Internal. Only to be used through TI provided API.
    1=CONT (Internal. Only to be used through TI provided API.); 0=SINGLE (Internal. Only to be used through TI provided API.)
  [18:17] ACCPERIOD rw — Internal. Only to be used through TI provided API.
    3=SMPL512 (Internal. Only to be used through TI provided API.); 2=SMPL128 (Internal. Only to be used through TI provided API.); 1=SMPL32 (Internal. Only to be used through TI provided API.); 0=SMPL8 (Internal. Only to be used through TI provided API.)
  [16] ACCEN rw — Internal. Only to be used through TI provided API.
    values as STRB1_STRB0.MLSETERM
  [15:9] RESERVED9 ro — Internal. Only to be used through TI provided API.
  [8:0] DSBUAVGLENGTH rw — Internal. Only to be used through TI provided API.
